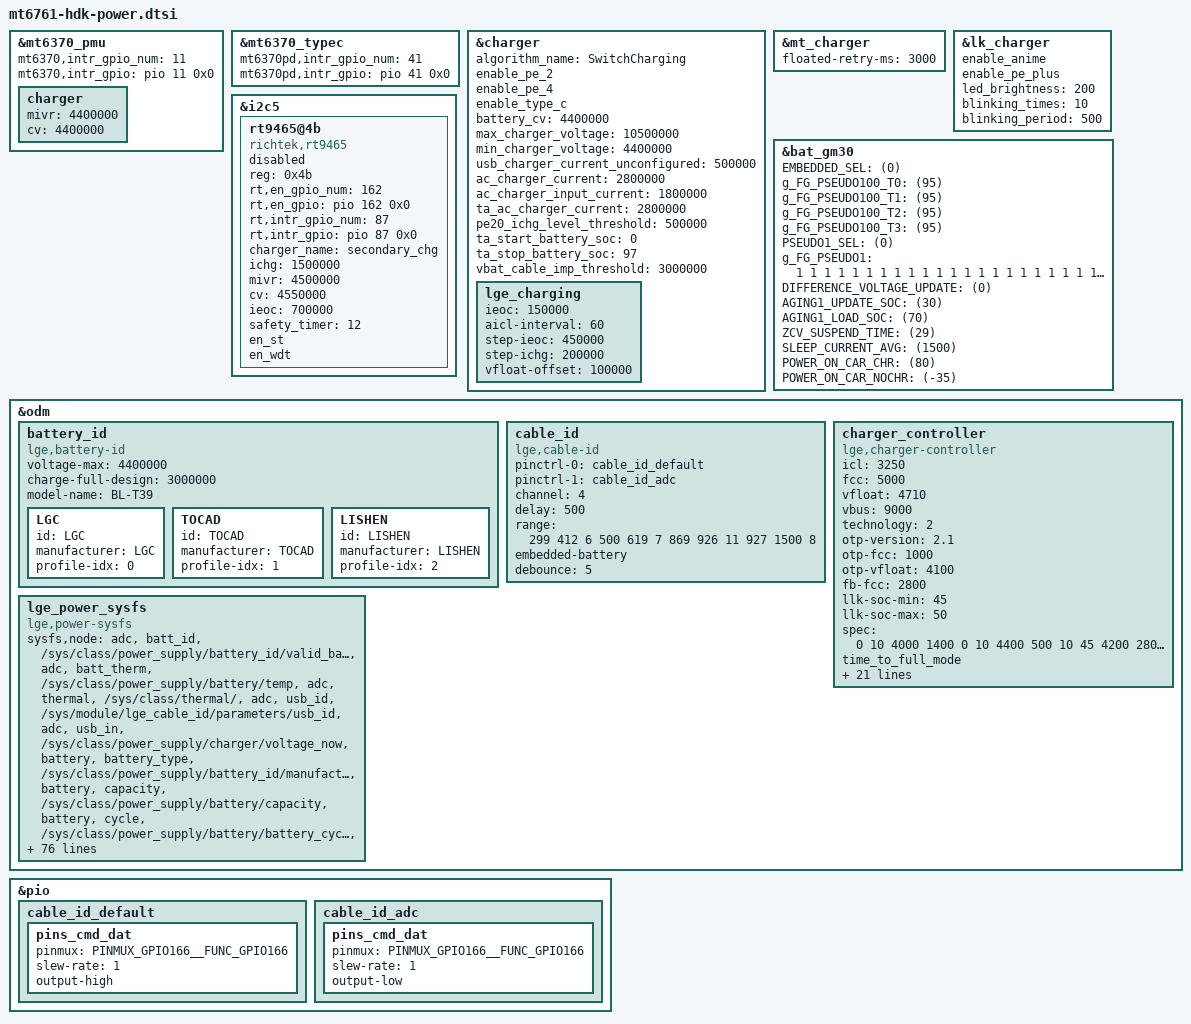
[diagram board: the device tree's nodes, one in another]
/*
 * LG Electronics MT6761 HDK power device tree source
 *
 * Copyright (c) 2018 LG Electronics Co., Ltd.
 *              http://www.lge.com
 *
 */

&mt6370_pmu {
	mt6370,intr_gpio_num = <11>; /* direct defined GPIO num */
	mt6370,intr_gpio = <&pio 11 0x0>;

	charger {
		interrupt-names = "chg_mivr", "chg_aiclmeasi",
			"attachi","ovpctrl_uvp_d_evt", "chg_wdtmri",
			"chg_vbusov","chg_tmri", "chg_treg", "pwr_rdy";
		mivr = <4400000>;	/* uV */
		cv = <4400000>;		/* uA */
	};
};

&mt6370_typec {
	mt6370pd,intr_gpio_num = <41>; /* direct defined GPIO num */
	mt6370pd,intr_gpio = <&pio 41 0x0>;
};

&charger {
	algorithm_name = "SwitchCharging";
	enable_pe_2;
	enable_pe_4;
	enable_type_c;

	/* common */
	battery_cv = <4400000>;
	max_charger_voltage = <10500000>;
	min_charger_voltage = <4400000>;

	/* usb charging curent */
	usb_charger_current_unconfigured = <500000>;

	/* charging current */
	ac_charger_current = <2800000>;
	ac_charger_input_current = <1800000>;
	ta_ac_charger_current = <2800000>;

	/* PE 2.0 */
	pe20_ichg_level_threshold = <500000>; /* uA */
	ta_start_battery_soc = <0>;
	ta_stop_battery_soc = <97>;

	/* cable measurement impedance */
	vbat_cable_imp_threshold = <3000000>; /* uV */

	/* LGE Charging Algorithm */
	lge_charging {
		ieoc = <150000>;
		aicl-interval = <60>;

		step-ieoc = <450000>;
		step-ichg = <200000>;
		vfloat-offset = <100000>;
	};
};

&mt_charger {
	floated-retry-ms = <3000>; /* 3000 ms */
};

&lk_charger {
	enable_anime;
	enable_pe_plus;
	led_brightness = <200>;
	blinking_times = <10>;
	blinking_period = <500>;
};

&i2c5 {
	rt9465@4b {
		compatible = "richtek,rt9465";
		reg = <0x4b>;
		status = "disabled";
		rt,en_gpio_num = <162>;
		rt,en_gpio = <&pio 162 0x0>;
		rt,intr_gpio_num = <87>; /* direct defined GPIO num */
		rt,intr_gpio = <&pio 87 0x0>;
		interrupt-names = "wdtmri";
		charger_name = "secondary_chg";
		ichg = <1500000>; /* uA */
		mivr = <4500000>; /* uV */
		cv = <4550000>; /* uV */
		ieoc = <700000>; /* uA */
		safety_timer = <12>; /* hour */
		en_st; /* safety timer */
		/* en_te; */
		en_wdt;
	};
};

&bat_gm30 {
	/*	Configures whether using embedded battery or not.*/
	EMBEDDED_SEL = <(0)>;

	/*      Pseudo 100% percentage at T0.*/
	g_FG_PSEUDO100_T0 = <(95)>;
	/*      Pseudo 100% percentage at T1.*/
	g_FG_PSEUDO100_T1 = <(95)>;
	/*      Pseudo 100% percentage at T2.*/
	g_FG_PSEUDO100_T2 = <(95)>;
	/*      Pseudo 100% percentage at T3.*/
	g_FG_PSEUDO100_T3 = <(95)>;

	PSEUDO1_SEL = <(0)>;

	g_FG_PSEUDO1 = <1  1  1  1
			1  1  1  1
			1  1  1  1
			1  1  1  1
			1  1  1  1
			1  1  1  1
			1  1  1  1
			1  1  1  1
			1  1  1  1
			1  1  1  1>;

	DIFFERENCE_VOLTAGE_UPDATE = <(0)>;
	AGING1_UPDATE_SOC = <(30)>;
	AGING1_LOAD_SOC = <(70)>;
	ZCV_SUSPEND_TIME = <(29)>;
	SLEEP_CURRENT_AVG = <(1500)>; /*0.1mA*/

	POWER_ON_CAR_CHR = <(80)>;
	POWER_ON_CAR_NOCHR = <(-35)>;

#include "../battery_BL-T39.dtsi"
};

&odm {
	/* Battery ID */
	battery_id {
		compatible = "lge,battery-id";
		voltage-max = <4400000>;
		charge-full-design = <3000000>;
		model-name = "BL-T39";

		LGC {
			id = "LGC";
			manufacturer = "LGC";
			profile-idx = <0>;
		};
		TOCAD {
			id = "TOCAD";
			manufacturer = "TOCAD";
			profile-idx = <1>;
		};
		LISHEN {
			id = "LISHEN";
			manufacturer = "LISHEN";
			profile-idx = <2>;
		};
	};

	/* Cable ID */
	cable_id {
		compatible = "lge,cable-id";
		pinctrl-names = "default", "adc";
		pinctrl-0 = <&cable_id_default>;
		pinctrl-1 = <&cable_id_adc>;

		channel = <4>;
		delay = <500>;

		/* Pull-up : 1.0V 100k, Accuracy(ADC) : +-10mV */
		range = <
		/*	min 	max 	type	*/
			299	412	6	/* 6: LT_CABLE_56K */
			500	619	7	/* 7: LT_CABLE_130K */
			869	926	11	/* 11: LT_CABLE_910K */
			927	1500	8	/* 8: USB_CABLE_400MA */
		>;

		embedded-battery;
		debounce = <5>;
	};

	/* Charger Controller */
	charger_controller {
		compatible = "lge,charger-controller";

		/* base information */
		icl = <3250>;
		fcc = <5000>;
		vfloat = <4710>;
		vbus = <9000>;
		technology = <2>;

		/* otp */
		otp-version = "2.1";
		otp-fcc = <1000>;
		otp-vfloat = <4100>;

		/* fb */
		fb-fcc = <2800>;

		/* llk */
		llk-soc-min = <45>;
		llk-soc-max = <50>;

		/* spec */
		spec = <
			 0 10 4000 1400	/* 0.5C */
			 0 10 4400 500	/* 0.2C */
			10 45 4200 2800	/* 1.0C */
			10 45 4400 1400	/* 0.5C */
			45 60 4100 1400	/* 0.5C */
		>;

		/* time to full */
		time_to_full_mode;
		battery_full_capacity = <3000>;
		sdp_current = <500>;
		dcp_current = <1200>;
		pep_current = <2680>;
		report_ttf_comp = <0>;
		sdp_comp = <(-10)>;
		dcp_comp = <0>;
		cdp_comp = <0>;
		min_comp = <0>;
				/* current soc */
		cc_data = <2680 0
				1380 540>;
				/* current soc time */
		cv_data = <1360 860 1430
				1346 870 1340
				1329 880 1260
				1297 890 1190
				1244 900 1100
				1162 910 1000
				1097 920 910
				1011 930 810
				981 940 760
				938 950 710
				873 960 600
				788 970 460
				711 980 310
				637 990 160
				569 1000 0>;

		/* restricted charging */
		restricted-LCD-ON = <2800>;
		restricted-TDMB-MODE1 = <500>;
		restricted-TDMB-MODE2 = <500>;

		/* game */
		game-fcc = <500>;

		game-light-fcc = <500>;
		game-light-load = <80>;
		game-light-sec = <100>;

		game-lowbatt-fcc = <500>;
		game-lowbatt-soc = <15>;
	};

	/* Unified Power Sysfs */
	lge_power_sysfs {
		compatible = "lge,power-sysfs";
		sysfs,node =
			/* adc group */
			"adc", "batt_id", "/sys/class/power_supply/battery_id/valid_batt_id",
			"adc", "batt_therm", "/sys/class/power_supply/battery/temp",
			"adc", "thermal", "/sys/class/thermal/",
			"adc", "usb_id", "/sys/module/lge_cable_id/parameters/usb_id",
			"adc", "usb_in", "/sys/class/power_supply/charger/voltage_now",
			/* battery group */
			"battery", "battery_type", "/sys/class/power_supply/battery_id/manufacturer",
			"battery", "capacity", "/sys/class/power_supply/battery/capacity",
			"battery", "cycle", "/sys/class/power_supply/battery/battery_cycle",
			"battery", "raw_capacity", "/sys/class/power_supply/battery/raw_capacity",
			"battery", "health", "/sys/class/power_supply/battery/health",
			"battery", "present", "/sys/class/power_supply/battery/present",
			"battery", "pseudo_batt", "/sys/module/pseudo_power_supply/parameters/pseudo_batt",
			"battery", "temp", "/sys/class/power_supply/battery/temp",
			"battery", "valid_batt_id", "/sys/class/power_supply/battery_id/valid_batt_id",
			"battery", "check_batt_id_for_aat", "/sys/class/power_supply/battery_id/check_batt_id_for_aat",
			"battery", "voltage_now", "/sys/class/power_supply/battery/voltage_now",
			"battery", "status", "/sys/class/power_supply/battery/status",
			"battery", "time_to_full_now", "/sys/class/power_supply/charger_controller/time_to_full_now",
			/* charger group */
			"charger", "ac_online", "/sys/class/power_supply/ac/online",
			"charger", "usb_online", "/sys/class/power_supply/usb/online",
			"charger", "present", "/sys/class/power_supply/charger/online",
			"charger", "ibat_current", "/sys/class/power_supply/battery/current_now",
			"charger", "ichg_current", "/sys/class/power_supply/usb/current_max",
			"charger", "charging_enabled", "/sys/class/power_supply/charger_controller/charging_enabled",
			"charger", "restricted_charging", "/sys/module/charger_controller/parameters/restricted_charging",
			"charger", "store_demo_enabled", "/sys/class/power_supply/charger_controller/store_demo_enabled",
			"charger", "fastchg", "/sys/class/power_supply/charger/fastchg",
			"charger", "fastchg_support", "/sys/class/power_supply/charger/fastchg_support",
			"charger", "incompatible", "/sys/class/power_supply/charger/incompatible_chg",
			"charger", "pseudo_hvdcp", "/sys/module/pseudo_power_supply/parameters/hvdcp_mode",
			"charger", "chgstep", "/sys/module/charger_controller/parameters/chgstep",
			/* lcd group */
			"lcd", "brightness", "/sys/class/leds/lcd-backlight/brightness",
			"lcd", "max_brightness", "/sys/class/leds/lcd-backlight/max_brightness",
			/* key led group */
			/* cpu group */
			"cpu", "game_mode", "/proc/ppm/policy/auto_game_limit",
			/* gpu group */
			/* platform group */
			/* perf service feature group */
			/* testmode group */
			"testmode", "batt_id", "/sys/class/power_supply/battery_id/batt_id",
			"testmode", "battexist", "/sys/class/power_supply/battery/present",
			"testmode", "charge", "/sys/module/charger_controller/parameters/atcmd_charge",
			"testmode", "chcomp", "/sys/module/charger_controller/parameters/atcmd_chcomp",
			"testmode", "chgmodeoff", "/sys/module/charger_controller/parameters/atcmd_chgmodeoff",
			"testmode", "current_max", "/sys/class/power_supply/usb/current_max",
			"testmode", "current_now", "/sys/class/power_supply/battery/current_now",
			"testmode", "fuelval", "/sys/class/power_supply/battery/capacity",
			"testmode", "temp", "/sys/module/charger_controller/parameters/atcmd_batmp",
			"testmode", "usb_id", "/sys/module/lge_cable_id/parameters/atcmd_usb_id",
			"testmode", "valid_batt_id", "/sys/class/power_supply/battery_id/check_batt_id_for_aat",
			"testmode", "voltage_now", "/sys/class/power_supply/battery/voltage_now";
	};
};

&pio {
	cable_id_default: cable_id_default {
		pins_cmd_dat {
			pinmux = <PINMUX_GPIO166__FUNC_GPIO166>;
			slew-rate = <1>;
			output-high;
		};
	};
	cable_id_adc: cable_id_adc {
		pins_cmd_dat {
			pinmux = <PINMUX_GPIO166__FUNC_GPIO166>;
			slew-rate = <1>;
			output-low;
		};
	};
};
